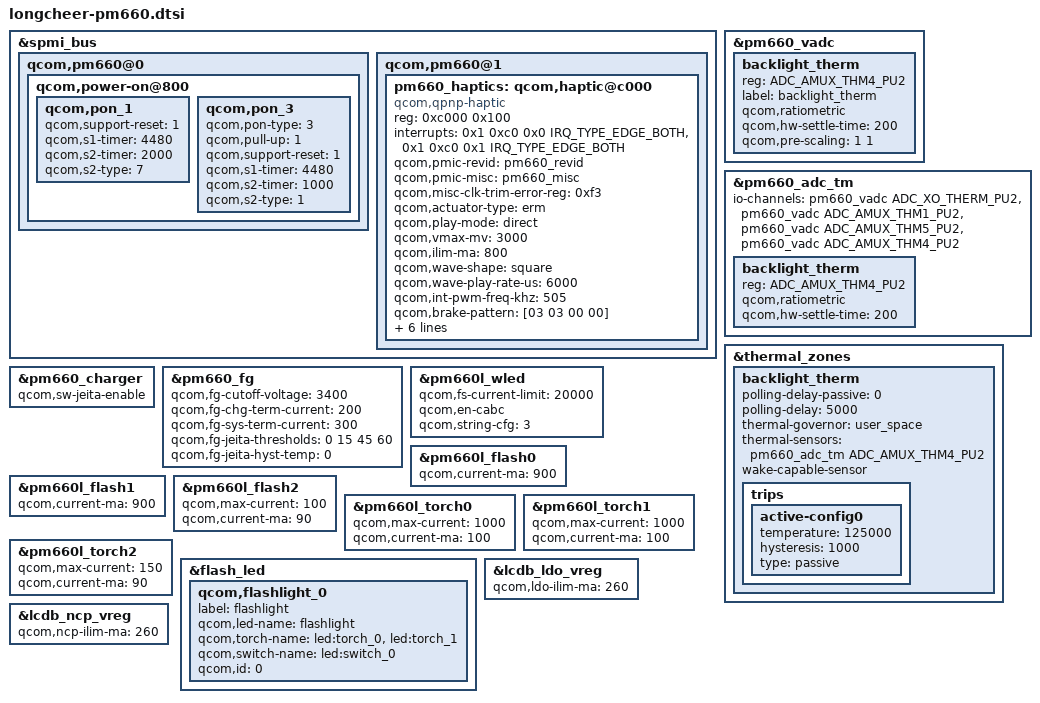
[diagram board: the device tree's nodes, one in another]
// SPDX-License-Identifier: GPL-2.0-only

/* common diff with msm-pm660.dtsi */
&spmi_bus {
	qcom,pm660@0 {
		qcom,power-on@800 {
			qcom,pon_1 {
				qcom,support-reset = <1>;
				qcom,s1-timer = <4480>;
				qcom,s2-timer = <2000>;
				qcom,s2-type = <7>;
			};

			qcom,pon_3 {
				qcom,pon-type = <3>;
				qcom,pull-up = <1>;
				qcom,support-reset = <1>;
				qcom,s1-timer = <4480>;
				qcom,s2-timer = <1000>;
				qcom,s2-type = <1>;
			};
		};
	};

	qcom,pm660@1 {
		/delete-node/ qcom,haptics@c000;
		pm660_haptics: qcom,haptic@c000 {
			compatible = "qcom,qpnp-haptic";
			reg = <0xc000 0x100>;
			interrupts = <0x1 0xc0 0x0 IRQ_TYPE_EDGE_BOTH>,
				     <0x1 0xc0 0x1 IRQ_TYPE_EDGE_BOTH>;
			interrupt-names = "sc-irq", "play-irq";
			qcom,pmic-revid = <&pm660_revid>;
			qcom,pmic-misc = <&pm660_misc>;
			qcom,misc-clk-trim-error-reg = <0xf3>;
			qcom,actuator-type = "erm";
			qcom,play-mode = "direct";
			qcom,vmax-mv = <3000>;
			qcom,ilim-ma = <800>;
			qcom,wave-shape = "square";
			qcom,wave-play-rate-us = <6000>;
			qcom,int-pwm-freq-khz = <505>;
			qcom,brake-pattern = [03 03 00 00];
			qcom,lra-high-z = "opt0";
			qcom,lra-auto-res-mode = "qwd";
			qcom,correct-lra-drive-freq;
			qcom,sc-deb-cycles = <8>;
			qcom,en-brake;
			qcom,lra-calibrate-at-eop = <0>;
		};
	};
};

&pm660_vadc {
	backlight_therm {
		reg = <ADC_AMUX_THM4_PU2>;
		label = "backlight_therm";
		qcom,ratiometric;
		qcom,hw-settle-time = <200>;
		qcom,pre-scaling = <1 1>;
	};
};

&pm660_adc_tm {
	io-channels = <&pm660_vadc ADC_XO_THERM_PU2>,
			<&pm660_vadc ADC_AMUX_THM1_PU2>,
			<&pm660_vadc ADC_AMUX_THM5_PU2>,
			<&pm660_vadc ADC_AMUX_THM4_PU2>;

	backlight_therm {
		reg = <ADC_AMUX_THM4_PU2>;
		qcom,ratiometric;
		qcom,hw-settle-time = <200>;
	};
};

&thermal_zones {
	backlight_therm {
		polling-delay-passive = <0>;
		polling-delay = <5000>;
		thermal-governor = "user_space";
		thermal-sensors = <&pm660_adc_tm ADC_AMUX_THM4_PU2>;
		wake-capable-sensor;
		trips {
			active-config0 {
				temperature = <125000>;
				hysteresis = <1000>;
				type = "passive";
			};
		};
	};
};

&pm660_charger {
	qcom,sw-jeita-enable;
};

&pm660_fg {
	qcom,fg-cutoff-voltage = <3400>;
	qcom,fg-chg-term-current = <200>;
	qcom,fg-sys-term-current = <300>;
	qcom,fg-jeita-thresholds = <0 15 45 60>;
	qcom,fg-jeita-hyst-temp = <0>;
};

/* common diff with msm-pm660l.dtsi */
&pm660l_wled {
	/delete-property/ qcom,auto-calibration;
	qcom,fs-current-limit = <20000>;
	qcom,en-cabc;
	qcom,string-cfg = <3>;
};

&pm660l_flash0 {
	qcom,current-ma = <900>;
};

&pm660l_flash1{
	qcom,current-ma = <900>;
};

&pm660l_flash2 {
	qcom,max-current = <100>;
	qcom,current-ma = <90>;
};

&pm660l_torch0 {
	qcom,max-current = <1000>;
	qcom,current-ma = <100>;
};

&pm660l_torch1 {
	qcom,max-current = <1000>;
	qcom,current-ma = <100>;
};

&pm660l_torch2 {
	qcom,max-current = <150>;
	qcom,current-ma = <90>;
};

&flash_led {
	qcom,flashlight_0 {
		label = "flashlight";
		qcom,led-name = "flashlight";
		qcom,torch-name = "led:torch_0", "led:torch_1";
		qcom,switch-name = "led:switch_0";
		qcom,id = <0>;
	};
};

&lcdb_ldo_vreg {
	qcom,ldo-ilim-ma = <260>;
};

&lcdb_ncp_vreg {
	qcom,ncp-ilim-ma = <260>;
};
